# ATSAMV71Q21 register map
Vendor: Microchip Technology; Series: SAMV71; File version: 0
CPU: CM7 r1p1, little endian, MPU, FPU, 3 interrupt priority bits
Registers are 32-bit, access not given, no defined reset value unless marked. A register's access mark holds for its fields unless they carry their own. Offsets are from the block's base; [hi:lo] are bit positions; {n}, {i} and the like mark numbered series.

## EFC — Embedded Flash Controller
Base 0x400E0C00; register names take the prefix EFC_
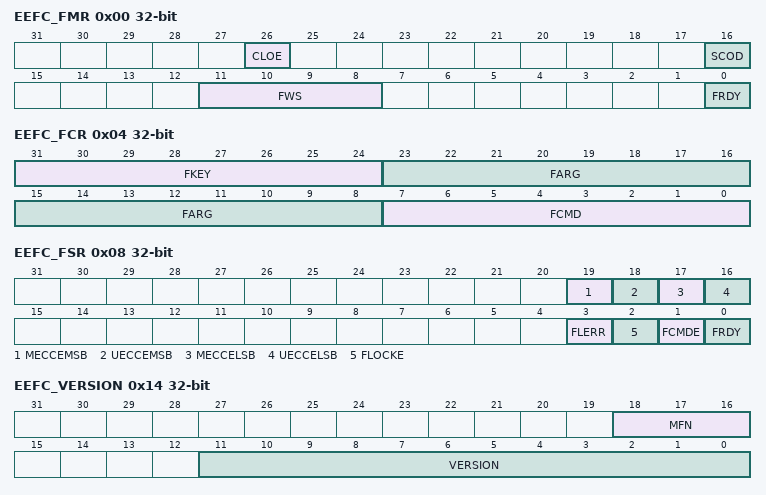
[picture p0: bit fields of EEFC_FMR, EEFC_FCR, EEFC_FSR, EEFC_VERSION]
0x00 EEFC_FMR — EEFC Flash Mode Register
  [26] CLOE — Code Loop Optimization Enable
  [16] SCOD — Sequential Code Optimization Disable
  [11:8] FWS — Flash Wait State
  [0] FRDY — Flash Ready Interrupt Enable
0x04 EEFC_FCR wo — EEFC Flash Command Register
  [31:24] FKEY — Flash Writing Protection Key
    90=PASSWD (The 0x5A value enables the command defined by the bits of the register. If the field is written with a different value, the write is not performed and no action is started.)
  [23:8] FARG — Flash Command Argument
  [7:0] FCMD — Flash Command
    0=GETD (Get Flash descriptor); 1=WP (Write page); 2=WPL (Write page and lock); 3=EWP (Erase page and write page); 4=EWPL (Erase page and write page then lock); 5=EA (Erase all); 7=EPA (Erase pages); 8=SLB (Set lock bit); 9=CLB (Clear lock bit); 10=GLB (Get lock bit); 11=SGPB (Set GPNVM bit); 12=CGPB (Clear GPNVM bit); 13=GGPB (Get GPNVM bit); 14=STUI (Start read unique identifier); 15=SPUI (Stop read unique identifier); 16=GCALB (Get CALIB bit); 17=ES (Erase sector); 18=WUS (Write user signature); 19=EUS (Erase user signature); 20=STUS (Start read user signature); 21=SPUS (Stop read user signature)
0x08 EEFC_FSR ro — EEFC Flash Status Register
  [19] MECCEMSB — Multiple ECC Error on MSB Part of the Memory Flash Data Bus (cleared on read)
  [18] UECCEMSB — Unique ECC Error on MSB Part of the Memory Flash Data Bus (cleared on read)
  [17] MECCELSB — Multiple ECC Error on LSB Part of the Memory Flash Data Bus (cleared on read)
  [16] UECCELSB — Unique ECC Error on LSB Part of the Memory Flash Data Bus (cleared on read)
  [3] FLERR — Flash Error Status (cleared when a programming operation starts)
  [2] FLOCKE — Flash Lock Error Status (cleared on read)
  [1] FCMDE — Flash Command Error Status (cleared on read or by writing EEFC_FCR)
  [0] FRDY — Flash Ready Status (cleared when Flash is busy)
0x0C EEFC_FRR ro — EEFC Flash Result Register
  [31:0] FVALUE — Flash Result Value
0x14 EEFC_VERSION ro
  [18:16] MFN — Metal Fix Number
  [11:0] VERSION — Version of the Hardware Module
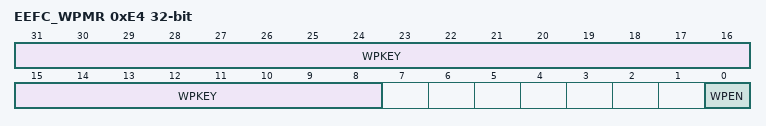
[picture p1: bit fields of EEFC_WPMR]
0xE4 EEFC_WPMR — Write Protection Mode Register
  [31:8] WPKEY — Write Protection Key
    0x454643=PASSWD (Writing any other value in this field aborts the write operation.Always reads as 0.)
  [0] WPEN — Write Protection Enable

## GPBR — General Purpose Backup Registers
Base 0x400E1890; register names take the prefix GPBR_
{0x0+4i} SYS_GPBR[{i}] (i=0..7) — General Purpose Backup Register 0
  [31:0] GPBR_VALUE — Value of GPBR x

## ICM — Integrity Check Monitor
Base 0x40048000; register names take the prefix ICM_
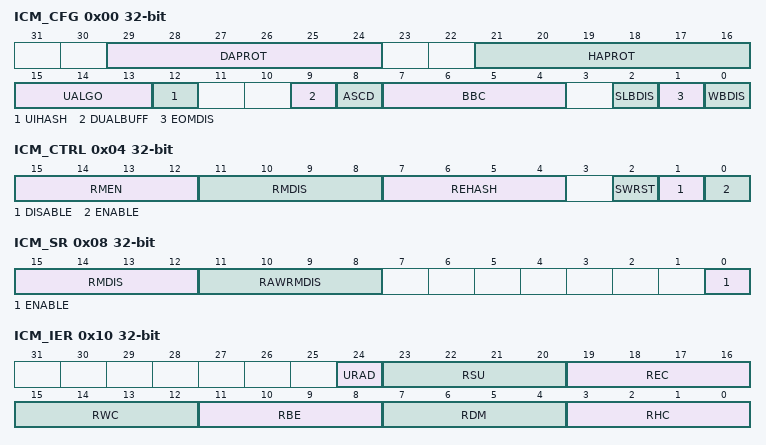
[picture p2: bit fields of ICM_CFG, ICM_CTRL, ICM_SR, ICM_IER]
0x00 ICM_CFG — Configuration Register
  [29:24] DAPROT — Region Descriptor Area Protection
  [21:16] HAPROT — Region Hash Area Protection
  [15:13] UALGO — User SHA Algorithm
    0=SHA1 (SHA1 algorithm processed); 1=SHA256 (SHA256 algorithm processed); 4=SHA224 (SHA224 algorithm processed)
  [12] UIHASH — User Initial Hash Value
  [9] DUALBUFF — Dual Input Buffer
  [8] ASCD — Automatic Switch To Compare Digest
  [7:4] BBC — Bus Burden Control
  [2] SLBDIS — Secondary List Branching Disable
  [1] EOMDIS — End of Monitoring Disable
  [0] WBDIS — Write Back Disable
0x04 ICM_CTRL wo — Control Register
  [15:12] RMEN — Region Monitoring Enable
  [11:8] RMDIS — Region Monitoring Disable
  [7:4] REHASH — Recompute Internal Hash
  [2] SWRST — Software Reset
  [1] DISABLE — ICM Disable Register
  [0] ENABLE — ICM Enable
0x08 ICM_SR ro — Status Register
  [15:12] RMDIS — Region Monitoring Disabled Status
  [11:8] RAWRMDIS — Region Monitoring Disabled Raw Status
  [0] ENABLE — ICM Controller Enable Register
0x10 ICM_IER wo — Interrupt Enable Register
  [24] URAD — Undefined Register Access Detection Interrupt Enable
  [23:20] RSU — Region Status Updated Interrupt Disable
  [19:16] REC — Region End bit Condition Detected Interrupt Enable
  [15:12] RWC — Region Wrap Condition detected Interrupt Enable
  [11:8] RBE — Region Bus Error Interrupt Enable
  [7:4] RDM — Region Digest Mismatch Interrupt Enable
  [3:0] RHC — Region Hash Completed Interrupt Enable
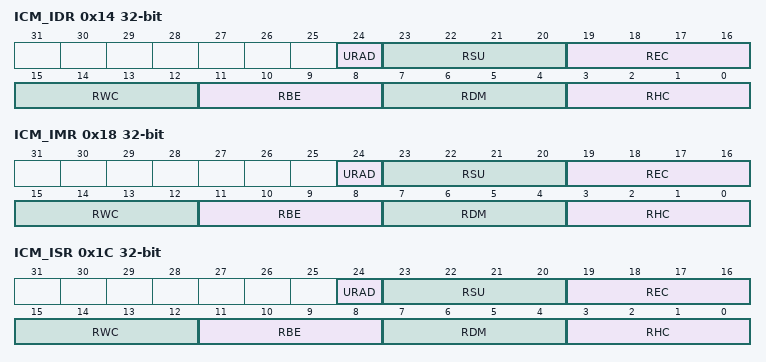
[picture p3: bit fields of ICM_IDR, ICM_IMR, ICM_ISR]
0x14 ICM_IDR wo — Interrupt Disable Register
  [24] URAD — Undefined Register Access Detection Interrupt Disable
  [23:20] RSU — Region Status Updated Interrupt Disable
  [19:16] REC — Region End bit Condition detected Interrupt Disable
  [15:12] RWC — Region Wrap Condition Detected Interrupt Disable
  [11:8] RBE — Region Bus Error Interrupt Disable
  [7:4] RDM — Region Digest Mismatch Interrupt Disable
  [3:0] RHC — Region Hash Completed Interrupt Disable
0x18 ICM_IMR ro — Interrupt Mask Register
  [24] URAD — Undefined Register Access Detection Interrupt Mask
  [23:20] RSU — Region Status Updated Interrupt Mask
  [19:16] REC — Region End bit Condition Detected Interrupt Mask
  [15:12] RWC — Region Wrap Condition Detected Interrupt Mask
  [11:8] RBE — Region Bus Error Interrupt Mask
  [7:4] RDM — Region Digest Mismatch Interrupt Mask
  [3:0] RHC — Region Hash Completed Interrupt Mask
0x1C ICM_ISR ro — Interrupt Status Register
  [24] URAD — Undefined Register Access Detection Status
  [23:20] RSU — Region Status Updated Detected
  [19:16] REC — Region End bit Condition Detected
  [15:12] RWC — Region Wrap Condition Detected
  [11:8] RBE — Region Bus Error
  [7:4] RDM — Region Digest Mismatch
  [3:0] RHC — Region Hash Completed
0x20 ICM_UASR ro — Undefined Access Status Register
  [2:0] URAT — Undefined Register Access Trace
    0=UNSPEC_STRUCT_MEMBER (Unspecified structure member set to one detected when the descriptor is loaded.); 1=ICM_CFG_MODIFIED (ICM_CFG modified during active monitoring.); 2=ICM_DSCR_MODIFIED (ICM_DSCR modified during active monitoring.); 3=ICM_HASH_MODIFIED (ICM_HASH modified during active monitoring); 4=READ_ACCESS (Write-only register read access)
0x30 ICM_DSCR — Region Descriptor Area Start Address Register
  [31:6] DASA — Descriptor Area Start Address
0x34 ICM_HASH — Region Hash Area Start Address Register
  [31:7] HASA — Hash Area Start Address
{0x38+4i} ICM_UIHVAL[{i}] (i=0..7) wo — User Initial Hash Value 0 Register 0
  [31:0] VAL — Initial Hash Value
